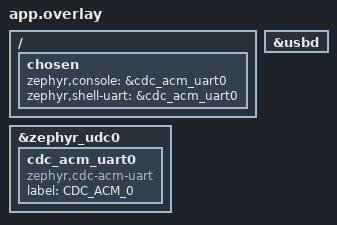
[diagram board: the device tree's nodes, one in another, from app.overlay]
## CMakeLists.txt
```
# ============================================================================
# CMakeLists.txt for DWM3001CDK USB CDC-ACM Hello World Application
# ============================================================================
# This file configures the build system for a USB CDC-ACM demonstration.
# The application prints messages to a virtual serial port over USB.

# Require CMake version 3.20.0 or higher (Zephyr minimum requirement)
cmake_minimum_required(VERSION 3.20.0)

# Locate the Zephyr build system and import its CMake functions/macros
# The HINTS path uses the ZEPHYR_BASE environment variable set by the SDK
find_package(Zephyr REQUIRED HINTS $ENV{ZEPHYR_BASE})

# Define the project name - this will be the application name
project(usb_hello)

# Specify source files to compile into the application
# The 'app' target is provided by Zephyr and represents our application binary
# We only have one source file: src/main.c
target_sources(app PRIVATE src/main.c)
```

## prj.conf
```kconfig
# ============================================================================
# DWM3001CDK USB CDC-ACM Hello World Configuration
# ============================================================================
# This configuration enables USB CDC-ACM (serial over USB) communication
# for console output and logging via connector J20.

# ============================================================================
# Core System Components
# ============================================================================

# Enable serial communication subsystem
# Foundation for UART/console communication (required for USB CDC)
CONFIG_SERIAL=y

# Enable console subsystem for debug output
# Allows the system to print messages to configured console device
CONFIG_CONSOLE=y

# Enable kernel printing functions (printk)
# Provides the actual printing APIs used in the application
CONFIG_PRINTK=y

# Enable runtime assertions
# Helps catch programming errors during development
CONFIG_ASSERT=y

# ============================================================================
# USB CDC-ACM Console Configuration
# ============================================================================

# Enable USB device stack
# Required for any USB device functionality on nRF52833
CONFIG_USB_DEVICE_STACK=y

# Enable USB CDC-ACM (Communication Device Class - Abstract Control Model)
# This creates a virtual serial port over USB that appears as /dev/ttyACM*
# on Linux or a COM port on Windows
CONFIG_USB_CDC_ACM=y

# Enable UART console subsystem
# Routes console output through UART devices (including USB CDC-ACM)
CONFIG_UART_CONSOLE=y

# ============================================================================
# Optional Features (Development/Debug Aids)
# ============================================================================

# Enable logging subsystem
# Provides structured logging capabilities beyond simple printk
CONFIG_LOG=y

# Set logging mode to immediate
# Log messages are printed immediately rather than being buffered
# This ensures timely output but may impact performance
CONFIG_LOG_MODE_IMMEDIATE=y

# ============================================================================
# USB Device Identification
# ============================================================================

# USB product string (appears in device manager/system information)
# This helps identify the device when multiple USB devices are connected
CONFIG_USB_DEVICE_PRODUCT="DWM3001CDK CDC ACM"

# USB Vendor ID (VID) and Product ID (PID)
# These identify the device to the host operating system:
# - VID 0x2FE3: Assigned to Qorvo (manufacturer of DWM3001CDK)
# - PID 0x0100: Product-specific identifier for this CDC-ACM device
CONFIG_USB_DEVICE_VID=0x2FE3
CONFIG_USB_DEVICE_PID=0x0100
```

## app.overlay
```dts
/**
 * @brief Device Tree Overlay for USB CDC-ACM Console
 *
 * This overlay configures the nRF52833 USB peripheral for CDC-ACM (serial over USB)
 * communication. It routes the system console output to a virtual serial port
 * accessible via USB connector J20 on the DWM3001CDK board.
 */

/ {
    /**
     * @brief System-wide device choices
     *
     * These properties tell Zephyr which devices to use for system services:
     * - zephyr,console: Where kernel messages (printk) are sent
     * - zephyr,shell-uart: Where the shell/console input/output goes
     *
     * Both are set to our USB CDC-ACM device for USB serial communication.
     */
    chosen {
        zephyr,console = &cdc_acm_uart0;     /* Route kernel prints to USB CDC */
        zephyr,shell-uart = &cdc_acm_uart0;  /* Route shell I/O to USB CDC */
    };
};

/**
 * @brief USB Device Controller Configuration
 *
 * Enable the USB device controller (UDC) on the nRF52833. This is required
 * for any USB device functionality including CDC-ACM serial communication.
 * The UDC handles the low-level USB protocol and packet management.
 */
&usbd {
    status = "okay";  /* Enable the USB device controller */
};

/**
 * @brief USB Device Controller Instance
 *
 * Configure the specific UDC instance (zephyr_udc0) and add our CDC-ACM
 * UART device to it. This creates a virtual serial port that appears
 * as /dev/ttyACM* on Linux or a COM port on Windows when connected via USB.
 */
&zephyr_udc0 {
    /**
     * @brief CDC-ACM UART Device Definition
     *
     * Creates a USB CDC-ACM (Communication Device Class - Abstract Control Model)
     * device that emulates a serial UART. This allows terminal applications
     * to communicate with the board as if it were a standard serial port.
     *
     * The label "CDC_ACM_0" can be used to reference this device in code
     * using DEVICE_DT_GET(DT_NODELABEL(cdc_acm_uart0)).
     */
    cdc_acm_uart0: cdc_acm_uart0 {
        compatible = "zephyr,cdc-acm-uart";  /* Use Zephyr's CDC-ACM UART driver */
        label = "CDC_ACM_0";                 /* Human-readable device identifier */
    };
};
```

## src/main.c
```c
/**
 * @file main.c
 * @brief USB CDC-ACM Hello World Application for DWM3001CDK
 *
 * This application demonstrates USB communication by printing messages
 * to a USB CDC-ACM (serial over USB) virtual serial port. It serves as
 * a validation test for USB connectivity and console output.
 */

#include <zephyr/kernel.h>          /* Kernel APIs: k_msleep() */
#include <zephyr/device.h>          /* Device management APIs */
#include <zephyr/drivers/uart.h>    /* UART driver APIs */
#include <zephyr/usb/usb_device.h>  /* USB device stack APIs */
#include <zephyr/sys/printk.h>      /* Print kernel logging APIs */

/**
 * @brief Wait for USB terminal connection before proceeding
 *
 * This function ensures that a USB terminal application (like screen, minicom,
 * or a serial monitor) has opened the virtual serial port before we start
 * printing messages. This prevents the loss of initial debug output.
 */
static void wait_for_dtr(void) {
    /* Get a reference to our USB CDC-ACM UART device defined in the overlay */
    const struct device *const dev = DEVICE_DT_GET(DT_NODELABEL(cdc_acm_uart0));

    /* If the device isn't ready, skip waiting (device might not be configured) */
    if (!device_is_ready(dev)) {
        return;
    }

    uint32_t dtr = 0;  /* Data Terminal Ready flag */

    /* Enable the USB device stack. Ignore errors if already enabled.
     * This brings up the USB peripheral and makes the CDC device visible
     * to the host computer. */
    (void)usb_enable(NULL);

    /* Poll the DTR (Data Terminal Ready) signal for up to 5 seconds.
     * DTR is set by terminal applications when they open the serial port.
     * We check every 500ms for a maximum of 10 attempts. */
    for (int i = 0; i < 10; ++i) {
        /* Query the current DTR state from the UART device */
        uart_line_ctrl_get(dev, UART_LINE_CTRL_DTR, &dtr);

        /* If DTR is set (terminal connected), we can proceed */
        if (dtr) {
            return;
        }

        /* Wait 500ms before checking again */
        k_msleep(500);
    }

    /* If we reach here, no terminal connected within 5 seconds.
     * We'll proceed anyway, but initial prints might be lost. */
}

/**
 * @brief Main application entry point
 *
 * Initializes USB communication, prints welcome messages, and enters
 * a heartbeat loop that periodically prints status messages.
 */
void main(void) {
    /* Initialize USB and wait for a terminal to connect.
     * This ensures our initial debug messages aren't lost. */
    wait_for_dtr();

    /* Print welcome banner with application information */
    printk("\n\n=== DWM3001CDK usb_hello ===\n");
    printk("Board up. Zephyr says hi from USB CDC (J20)!\n");

    /* Print build timestamp for version tracking */
    printk("Build: %s %s\n", __DATE__, __TIME__);

    /* Main application loop - print periodic heartbeat messages.
     * This loop runs forever and provides ongoing proof that the
     * application is running and USB communication is working. */
    while (1) {
        /* Print a simple heartbeat message */
        printk("tick\n");

        /* Sleep for 1 second before next heartbeat.
         * This creates a 1 Hz heartbeat pattern. */
        k_msleep(1000);
    }
}
```
